AUTOSAR XML (schema 00046)
package /ComponentTypes
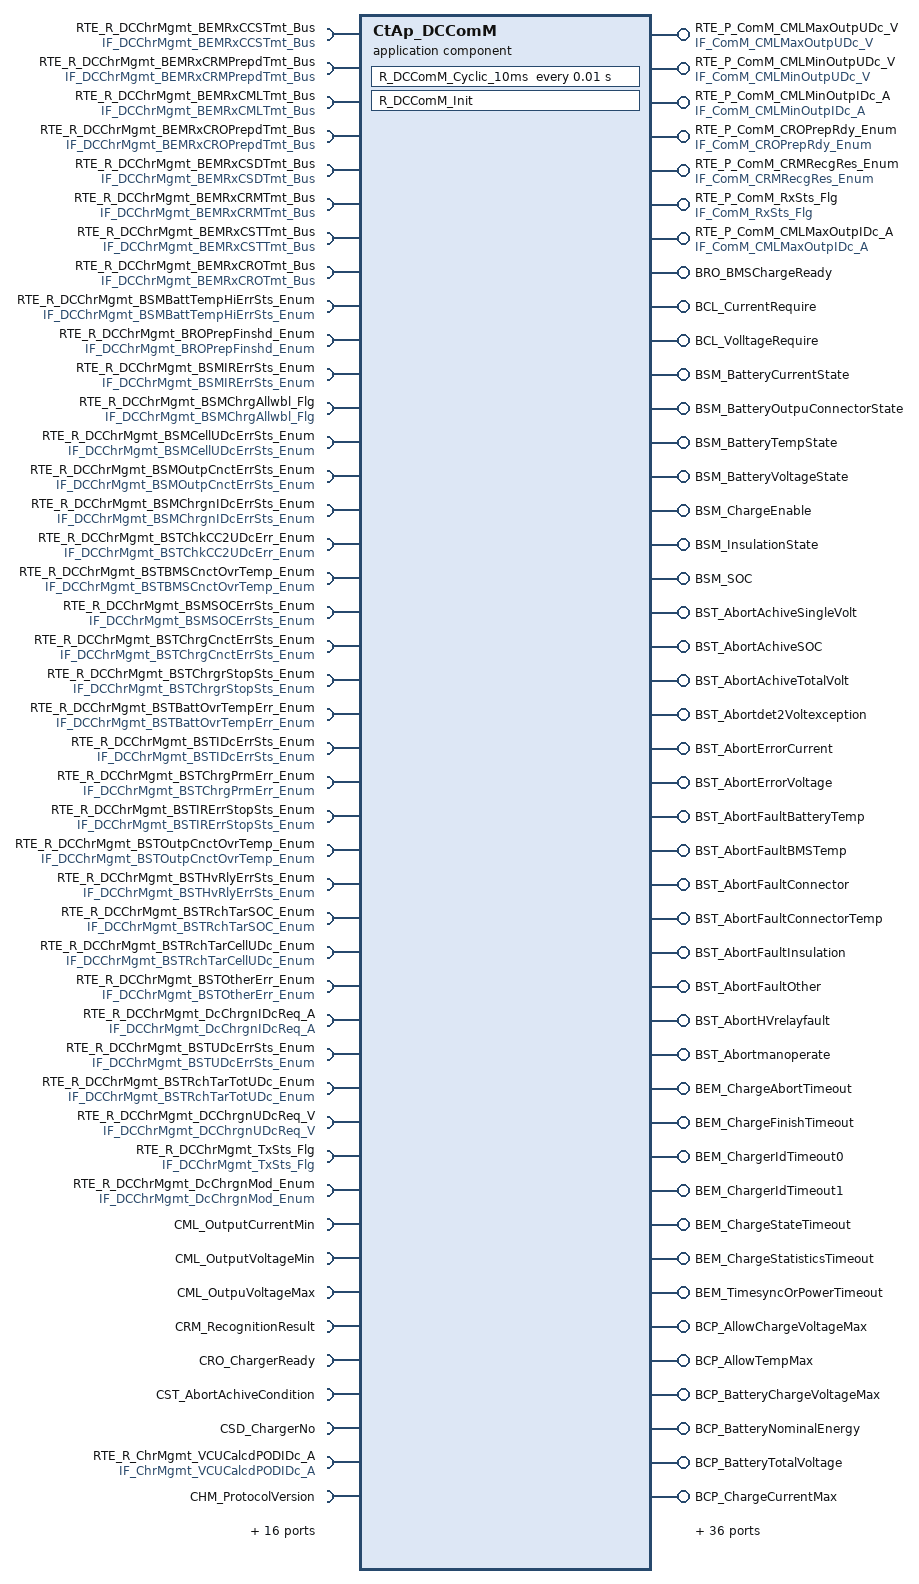
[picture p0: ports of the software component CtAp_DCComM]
  application sw component type CtAp_DCComM
    7 x provide port:
      RTE_P_ComM_CMLMaxOutpUDc_V: nonqueued-sender-com-spec{data-element=tec_ComM_CMLMaxOutpUDc_V, init-value=0}, provided-interface=IF_ComM_CMLMaxOutpUDc_V
      RTE_P_ComM_CMLMinOutpUDc_V: nonqueued-sender-com-spec{data-element=tec_ComM_CMLMinOutpUDc_V, init-value=0}, provided-interface=IF_ComM_CMLMinOutpUDc_V
      RTE_P_ComM_CMLMinOutpIDc_A: nonqueued-sender-com-spec{data-element=tec_ComM_CMLMinOutpIDc_A, init-value=0}, provided-interface=IF_ComM_CMLMinOutpIDc_A
      RTE_P_ComM_CROPrepRdy_Enum: nonqueued-sender-com-spec{data-element=tec_ComM_CROPrepRdy_Enum, init-value=0}, provided-interface=IF_ComM_CROPrepRdy_Enum
      RTE_P_ComM_CRMRecgRes_Enum: nonqueued-sender-com-spec{data-element=tec_ComM_CRMRecgRes_Enum, init-value=0}, provided-interface=IF_ComM_CRMRecgRes_Enum
      RTE_P_ComM_RxSts_Flg: provided-interface=IF_ComM_RxSts_Flg
        provided-com-specs:
          data-element=tec_ComM_RxCROSts_Flg, init-value=0
          data-element=tec_ComM_RxCEMSts_Flg, init-value=0
          data-element=tec_ComM_RxCHMSts_Flg, init-value=0
          data-element=tec_ComM_RxCSTSts_Flg, init-value=0
          data-element=tec_ComM_RxCSDSts_Flg, init-value=0
          data-element=tec_ComM_RxCCSSts_Flg, init-value=0
          data-element=tec_ComM_RxCMLSts_Flg, init-value=0
          data-element=tec_ComM_RxCRMSts_Flg, init-value=0
      RTE_P_ComM_CMLMaxOutpIDc_A: nonqueued-sender-com-spec{data-element=tec_ComM_CMLMaxOutpIDc_A, init-value=0}, provided-interface=IF_ComM_CMLMaxOutpIDc_A
    35 x require port:
      RTE_R_DCChrMgmt_BEMRxCCSTmt_Bus: nonqueued-receiver-com-spec{data-element=tec_DCChrMgmt_BEMRxCCSTmt_Bus, filter=data-filter-type=ALWAYS, init-value=fields=[DCChrMgmt_MonStatBEMRxCCSTmt:0, DCChrMgmt_MonResBEMRxCCSTmt:0, DCChrMgmt_ErrStatBEMRxCCSTmt:0, DCChrMgmt_ErrResBEMRxCCSTmt:0]}, required-interface=IF_DCChrMgmt_BEMRxCCSTmt_Bus
      RTE_R_DCChrMgmt_BEMRxCRMPrepdTmt_Bus: nonqueued-receiver-com-spec{data-element=tec_DCChrMgmt_BEMRxCRMPrepdTmt_Bus, filter=data-filter-type=ALWAYS, init-value=fields=[DCChrMgmt_MonStatBEMRxCRMPrepdTmt:0, DCChrMgmt_MonResBEMRxCRMPrepdTmt:0, DCChrMgmt_ErrStatBEMRxCRMPrepdTmt:0, DCChrMgmt_ErrResBEMRxCRMPrepdTmt:0]}, required-interface=IF_DCChrMgmt_BEMRxCRMPrepdTmt_Bus
      RTE_R_DCChrMgmt_BEMRxCMLTmt_Bus: nonqueued-receiver-com-spec{data-element=tec_DCChrMgmt_BEMRxCMLTmt_Bus, filter=data-filter-type=ALWAYS, init-value=fields=[DCChrMgmt_MonStatBEMRxCMLTmt:0, DCChrMgmt_MonResBEMRxCMLTmt:0, DCChrMgmt_ErrStatBEMRxCMLTmt:0, DCChrMgmt_ErrResBEMRxCMLTmt:0]}, required-interface=IF_DCChrMgmt_BEMRxCMLTmt_Bus
      RTE_R_DCChrMgmt_BEMRxCROPrepdTmt_Bus: nonqueued-receiver-com-spec{data-element=tec_DCChrMgmt_BEMRxCROPrepdTmt_Bus, filter=data-filter-type=ALWAYS, init-value=fields=[DCChrMgmt_MonStatBEMRxCROPrepdTmt:0, DCChrMgmt_MonResBEMRxCROPrepdTmt:0, DCChrMgmt_ErrStatBEMRxCROPrepdTmt:0, DCChrMgmt_ErrResBEMRxCROPrepdTmt:0]}, required-interface=IF_DCChrMgmt_BEMRxCROPrepdTmt_Bus
      RTE_R_DCChrMgmt_BEMRxCSDTmt_Bus: nonqueued-receiver-com-spec{data-element=tec_DCChrMgmt_BEMRxCSDTmt_Bus, filter=data-filter-type=ALWAYS, init-value=fields=[DCChrMgmt_MonStatBEMRxCSDTmt:0, DCChrMgmt_MonResBEMRxCSDTmt:0, DCChrMgmt_ErrStatBEMRxCSDTmt:0, DCChrMgmt_ErrResBEMRxCSDTmt:0]}, required-interface=IF_DCChrMgmt_BEMRxCSDTmt_Bus
      RTE_R_DCChrMgmt_BEMRxCRMTmt_Bus: nonqueued-receiver-com-spec{data-element=tec_DCChrMgmt_BEMRxCRMTmt_Bus, filter=data-filter-type=ALWAYS, init-value=fields=[DCChrMgmt_MonStatBEMRxCRMTmt:0, DCChrMgmt_MonResBEMRxCRMTmt:0, DCChrMgmt_ErrStatBEMRxCRMTmt:0, DCChrMgmt_ErrResBEMRxCRMTmt:0]}, required-interface=IF_DCChrMgmt_BEMRxCRMTmt_Bus
      RTE_R_DCChrMgmt_BEMRxCSTTmt_Bus: nonqueued-receiver-com-spec{data-element=tec_DCChrMgmt_BEMRxCSTTmt_Bus, filter=data-filter-type=ALWAYS, init-value=fields=[DCChrMgmt_MonStatBEMRxCSTTmt:0, DCChrMgmt_MonResBEMRxCSTTmt:0, DCChrMgmt_ErrStatBEMRxCSTTmt:0, DCChrMgmt_ErrResBEMRxCSTTmt:0]}, required-interface=IF_DCChrMgmt_BEMRxCSTTmt_Bus
      RTE_R_DCChrMgmt_BEMRxCROTmt_Bus: nonqueued-receiver-com-spec{data-element=tec_DCChrMgmt_BEMRxCROTmt_Bus, filter=data-filter-type=ALWAYS, init-value=fields=[DCChrMgmt_MonStatBEMRxCROTmt:0, DCChrMgmt_MonResBEMRxCROTmt:0, DCChrMgmt_ErrStatBEMRxCROTmt:0, DCChrMgmt_ErrResBEMRxCROTmt:0]}, required-interface=IF_DCChrMgmt_BEMRxCROTmt_Bus
      RTE_R_DCChrMgmt_BSMBattTempHiErrSts_Enum: nonqueued-receiver-com-spec{data-element=tec_DCChrMgmt_BSMBattTempHiErrSts_Enum, filter=data-filter-type=ALWAYS, init-value=0}, required-interface=IF_DCChrMgmt_BSMBattTempHiErrSts_Enum
      RTE_R_DCChrMgmt_BROPrepFinshd_Enum: nonqueued-receiver-com-spec{data-element=tec_DCChrMgmt_BROPrepFinshd_Enum, filter=data-filter-type=ALWAYS, init-value=0}, required-interface=IF_DCChrMgmt_BROPrepFinshd_Enum
      RTE_R_DCChrMgmt_BSMIRErrSts_Enum: nonqueued-receiver-com-spec{data-element=tec_DCChrMgmt_BSMIRErrSts_Enum, filter=data-filter-type=ALWAYS, init-value=0}, required-interface=IF_DCChrMgmt_BSMIRErrSts_Enum
      RTE_R_DCChrMgmt_BSMChrgAllwbl_Flg: nonqueued-receiver-com-spec{data-element=tec_DCChrMgmt_BSMChrgAllwbl_Flg, filter=data-filter-type=ALWAYS, init-value=0}, required-interface=IF_DCChrMgmt_BSMChrgAllwbl_Flg
      RTE_R_DCChrMgmt_BSMCellUDcErrSts_Enum: nonqueued-receiver-com-spec{data-element=tec_DCChrMgmt_BSMCellUDcErrSts_Enum, filter=data-filter-type=ALWAYS, init-value=0}, required-interface=IF_DCChrMgmt_BSMCellUDcErrSts_Enum
      RTE_R_DCChrMgmt_BSMOutpCnctErrSts_Enum: nonqueued-receiver-com-spec{data-element=tec_DCChrMgmt_BSMOutpCnctErrSts_Enum, filter=data-filter-type=ALWAYS, init-value=0}, required-interface=IF_DCChrMgmt_BSMOutpCnctErrSts_Enum
      RTE_R_DCChrMgmt_BSMChrgnIDcErrSts_Enum: nonqueued-receiver-com-spec{data-element=tec_DCChrMgmt_BSMChrgnIDcErrSts_Enum, filter=data-filter-type=ALWAYS, init-value=0}, required-interface=IF_DCChrMgmt_BSMChrgnIDcErrSts_Enum
      RTE_R_DCChrMgmt_BSTChkCC2UDcErr_Enum: nonqueued-receiver-com-spec{data-element=tec_DCChrMgmt_BSTChkCC2UDcErr_Enum, filter=data-filter-type=ALWAYS, init-value=0}, required-interface=IF_DCChrMgmt_BSTChkCC2UDcErr_Enum
      RTE_R_DCChrMgmt_BSTBMSCnctOvrTemp_Enum: nonqueued-receiver-com-spec{data-element=tec_DCChrMgmt_BSTBMSCnctOvrTemp_Enum, filter=data-filter-type=ALWAYS, init-value=0}, required-interface=IF_DCChrMgmt_BSTBMSCnctOvrTemp_Enum
      RTE_R_DCChrMgmt_BSMSOCErrSts_Enum: nonqueued-receiver-com-spec{data-element=tec_DCChrMgmt_BSMSOCErrSts_Enum, filter=data-filter-type=ALWAYS, init-value=0}, required-interface=IF_DCChrMgmt_BSMSOCErrSts_Enum
      RTE_R_DCChrMgmt_BSTChrgCnctErrSts_Enum: nonqueued-receiver-com-spec{data-element=tec_DCChrMgmt_BSTChrgCnctErrSts_Enum, filter=data-filter-type=ALWAYS, init-value=0}, required-interface=IF_DCChrMgmt_BSTChrgCnctErrSts_Enum
      RTE_R_DCChrMgmt_BSTChrgrStopSts_Enum: nonqueued-receiver-com-spec{data-element=tec_DCChrMgmt_BSTChrgrStopSts_Enum, filter=data-filter-type=ALWAYS, init-value=0}, required-interface=IF_DCChrMgmt_BSTChrgrStopSts_Enum
      RTE_R_DCChrMgmt_BSTBattOvrTempErr_Enum: nonqueued-receiver-com-spec{data-element=tec_DCChrMgmt_BSTBattOvrTempErr_Enum, filter=data-filter-type=ALWAYS, init-value=0}, required-interface=IF_DCChrMgmt_BSTBattOvrTempErr_Enum
      RTE_R_DCChrMgmt_BSTIDcErrSts_Enum: nonqueued-receiver-com-spec{data-element=tec_DCChrMgmt_BSTIDcErrSts_Enum, filter=data-filter-type=ALWAYS, init-value=0}, required-interface=IF_DCChrMgmt_BSTIDcErrSts_Enum
      RTE_R_DCChrMgmt_BSTChrgPrmErr_Enum: nonqueued-receiver-com-spec{data-element=tec_DCChrMgmt_BSTChrgPrmErr_Enum, filter=data-filter-type=ALWAYS, init-value=0}, required-interface=IF_DCChrMgmt_BSTChrgPrmErr_Enum
      RTE_R_DCChrMgmt_BSTIRErrStopSts_Enum: nonqueued-receiver-com-spec{data-element=tec_DCChrMgmt_BSTIRErrStopSts_Enum, filter=data-filter-type=ALWAYS, init-value=0}, required-interface=IF_DCChrMgmt_BSTIRErrStopSts_Enum
      RTE_R_DCChrMgmt_BSTOutpCnctOvrTemp_Enum: nonqueued-receiver-com-spec{data-element=tec_DCChrMgmt_BSTOutpCnctOvrTemp_Enum, filter=data-filter-type=ALWAYS, init-value=0}, required-interface=IF_DCChrMgmt_BSTOutpCnctOvrTemp_Enum
      RTE_R_DCChrMgmt_BSTHvRlyErrSts_Enum: nonqueued-receiver-com-spec{data-element=tec_DCChrMgmt_BSTHvRlyErrSts_Enum, filter=data-filter-type=ALWAYS, init-value=0}, required-interface=IF_DCChrMgmt_BSTHvRlyErrSts_Enum
      RTE_R_DCChrMgmt_BSTRchTarSOC_Enum: nonqueued-receiver-com-spec{data-element=tec_DCChrMgmt_BSTRchTarSOC_Enum, filter=data-filter-type=ALWAYS, init-value=0}, required-interface=IF_DCChrMgmt_BSTRchTarSOC_Enum
      RTE_R_DCChrMgmt_BSTRchTarCellUDc_Enum: nonqueued-receiver-com-spec{data-element=tec_DCChrMgmt_BSTRchTarCellUDc_Enum, filter=data-filter-type=ALWAYS, init-value=0}, required-interface=IF_DCChrMgmt_BSTRchTarCellUDc_Enum
      RTE_R_DCChrMgmt_BSTOtherErr_Enum: nonqueued-receiver-com-spec{data-element=tec_DCChrMgmt_BSTOtherErr_Enum, filter=data-filter-type=ALWAYS, init-value=0}, required-interface=IF_DCChrMgmt_BSTOtherErr_Enum
      RTE_R_DCChrMgmt_DcChrgnIDcReq_A: nonqueued-receiver-com-spec{data-element=tec_DCChrMgmt_DcChrgnIDcReq_A, filter=data-filter-type=ALWAYS, init-value=0}, required-interface=IF_DCChrMgmt_DcChrgnIDcReq_A
      RTE_R_DCChrMgmt_BSTUDcErrSts_Enum: nonqueued-receiver-com-spec{data-element=tec_DCChrMgmt_BSTUDcErrSts_Enum, filter=data-filter-type=ALWAYS, init-value=0}, required-interface=IF_DCChrMgmt_BSTUDcErrSts_Enum
      RTE_R_DCChrMgmt_BSTRchTarTotUDc_Enum: nonqueued-receiver-com-spec{data-element=tec_DCChrMgmt_BSTRchTarTotUDc_Enum, filter=data-filter-type=ALWAYS, init-value=0}, required-interface=IF_DCChrMgmt_BSTRchTarTotUDc_Enum
      RTE_R_DCChrMgmt_DCChrgnUDcReq_V: nonqueued-receiver-com-spec{data-element=tec_DCChrMgmt_DcChrgnUDcReq_V, filter=data-filter-type=ALWAYS, init-value=0}, required-interface=IF_DCChrMgmt_DCChrgnUDcReq_V
      RTE_R_DCChrMgmt_TxSts_Flg: required-interface=IF_DCChrMgmt_TxSts_Flg
        required-com-specs:
          data-element=tec_DCChrMgmt_TxBSDSts_Flg, filter=data-filter-type=ALWAYS, init-value=0
          data-element=tec_DCChrMgmt_TxBEMSts_Flg, filter=data-filter-type=ALWAYS, init-value=0
          data-element=tec_DCChrMgmt_TxBSMSts_Flg, filter=data-filter-type=ALWAYS, init-value=0
          data-element=tec_DCChrMgmt_TxBCSSts_Flg, filter=data-filter-type=ALWAYS, init-value=0
          data-element=tec_DCChrMgmt_TxBSTSts_Flg, filter=data-filter-type=ALWAYS, init-value=0
          data-element=tec_DCChrMgmt_TxBCLSts_Flg, filter=data-filter-type=ALWAYS, init-value=0
          data-element=tec_DCChrMgmt_TxBROSts_Flg, filter=data-filter-type=ALWAYS, init-value=0
          data-element=tec_DCChrMgmt_TxBCPSts_Flg, filter=data-filter-type=ALWAYS, init-value=0
          data-element=tec_DCChrMgmt_TxBRMSts_Flg, filter=data-filter-type=ALWAYS, init-value=0
          data-element=tec_DCChrMgmt_TxBHMSts_Flg, filter=data-filter-type=ALWAYS, init-value=0
      RTE_R_DCChrMgmt_DcChrgnMod_Enum: nonqueued-receiver-com-spec{data-element=tec_DCChrMgmt_DcChrgnMod_Enum, filter=data-filter-type=ALWAYS, init-value=0}, required-interface=IF_DCChrMgmt_DcChrgnMod_Enum
    31 x provide port:
      BRO_BMSChargeReady: nonqueued-sender-com-spec{data-element=BRO_BMSChargeReady, init-value=0}, provided-interface=BRO_BMSChargeReady
      BCL_CurrentRequire: nonqueued-sender-com-spec{data-element=BCL_CurrentRequire, init-value=-400}, provided-interface=BCL_CurrentRequire
      BCL_VolltageRequire: nonqueued-sender-com-spec{data-element=BCL_VolltageRequire, init-value=0}, provided-interface=BCL_VolltageRequire
      BSM_BatteryCurrentState: nonqueued-sender-com-spec{data-element=BSM_BatteryCurrentState, init-value=0}, provided-interface=BSM_BatteryCurrentState
      BSM_BatteryOutpuConnectorState: nonqueued-sender-com-spec{data-element=BSM_BatteryOutpuConnectorState, init-value=0}, provided-interface=BSM_BatteryOutpuConnectorState
      BSM_BatteryTempState: nonqueued-sender-com-spec{data-element=BSM_BatteryTempState, init-value=0}, provided-interface=BSM_BatteryTempState
      BSM_BatteryVoltageState: nonqueued-sender-com-spec{data-element=BSM_BatteryVoltageState, init-value=0}, provided-interface=BSM_BatteryVoltageState
      BSM_ChargeEnable: nonqueued-sender-com-spec{data-element=BSM_ChargeEnable, init-value=0}, provided-interface=BSM_ChargeEnable
      BSM_InsulationState: nonqueued-sender-com-spec{data-element=BSM_InsulationState, init-value=0}, provided-interface=BSM_InsulationState
      BSM_SOC: nonqueued-sender-com-spec{data-element=BSM_SOC, init-value=0}, provided-interface=BSM_SOC
      BST_AbortAchiveSingleVolt: nonqueued-sender-com-spec{data-element=BST_AbortAchiveSingleVolt, init-value=0}, provided-interface=BST_AbortAchiveSingleVolt
      BST_AbortAchiveSOC: nonqueued-sender-com-spec{data-element=BST_AbortAchiveSOC, init-value=0}, provided-interface=BST_AbortAchiveSOC
      BST_AbortAchiveTotalVolt: nonqueued-sender-com-spec{data-element=BST_AbortAchiveTotalVolt, init-value=0}, provided-interface=BST_AbortAchiveTotalVolt
      BST_Abortdet2Voltexception: nonqueued-sender-com-spec{data-element=BST_Abortdet2Voltexception, init-value=0}, provided-interface=BST_Abortdet2Voltexception
      BST_AbortErrorCurrent: nonqueued-sender-com-spec{data-element=BST_AbortErrorCurrent, init-value=0}, provided-interface=BST_AbortErrorCurrent
      BST_AbortErrorVoltage: nonqueued-sender-com-spec{data-element=BST_AbortErrorVoltage, init-value=0}, provided-interface=BST_AbortErrorVoltage
      BST_AbortFaultBatteryTemp: nonqueued-sender-com-spec{data-element=BST_AbortFaultBatteryTemp, init-value=0}, provided-interface=BST_AbortFaultBatteryTemp
      BST_AbortFaultBMSTemp: nonqueued-sender-com-spec{data-element=BST_AbortFaultBMSTemp, init-value=0}, provided-interface=BST_AbortFaultBMSTemp
      BST_AbortFaultConnector: nonqueued-sender-com-spec{data-element=BST_AbortFaultConnector, init-value=0}, provided-interface=BST_AbortFaultConnector
      BST_AbortFaultConnectorTemp: nonqueued-sender-com-spec{data-element=BST_AbortFaultConnectorTemp, init-value=0}, provided-interface=BST_AbortFaultConnectorTemp
      BST_AbortFaultInsulation: nonqueued-sender-com-spec{data-element=BST_AbortFaultInsulation, init-value=0}, provided-interface=BST_AbortFaultInsulation
      BST_AbortFaultOther: nonqueued-sender-com-spec{data-element=BST_AbortFaultOther, init-value=0}, provided-interface=BST_AbortFaultOther
      BST_AbortHVrelayfault: nonqueued-sender-com-spec{data-element=BST_AbortHVrelayfault, init-value=0}, provided-interface=BST_AbortHVrelayfault
      BST_Abortmanoperate: nonqueued-sender-com-spec{data-element=BST_Abortmanoperate, init-value=0}, provided-interface=BST_Abortmanoperate
      BEM_ChargeAbortTimeout: nonqueued-sender-com-spec{data-element=BEM_ChargeAbortTimeout, init-value=0}, provided-interface=BEM_ChargeAbortTimeout
      BEM_ChargeFinishTimeout: nonqueued-sender-com-spec{data-element=BEM_ChargeFinishTimeout, init-value=0}, provided-interface=BEM_ChargeFinishTimeout
      BEM_ChargerIdTimeout0: nonqueued-sender-com-spec{data-element=BEM_ChargerIdTimeout0, init-value=0}, provided-interface=BEM_ChargerIdTimeout0
      BEM_ChargerIdTimeout1: nonqueued-sender-com-spec{data-element=BEM_ChargerIdTimeout1, init-value=0}, provided-interface=BEM_ChargerIdTimeout1
      BEM_ChargeStateTimeout: nonqueued-sender-com-spec{data-element=BEM_ChargeStateTimeout, init-value=0}, provided-interface=BEM_ChargeStateTimeout
      BEM_ChargeStatisticsTimeout: nonqueued-sender-com-spec{data-element=BEM_ChargeStatisticsTimeout, init-value=0}, provided-interface=BEM_ChargeStatisticsTimeout
      BEM_TimesyncOrPowerTimeout: nonqueued-sender-com-spec{data-element=BEM_TimesyncOrPowerTimeout, init-value=0}, provided-interface=BEM_TimesyncOrPowerTimeout
    8 x require port:
      CML_OutputCurrentMin: nonqueued-receiver-com-spec{data-element=CML_OutputCurrentMin, init-value=0}, required-interface=CML_OutputCurrentMin
      CML_OutputVoltageMin: nonqueued-receiver-com-spec{data-element=CML_OutputVoltageMin, init-value=0}, required-interface=CML_OutputVoltageMin
      CML_OutpuVoltageMax: nonqueued-receiver-com-spec{data-element=CML_OutpuVoltageMax, enable-update=true, init-value=0}, required-interface=CML_OutpuVoltageMax
      CRM_RecognitionResult: nonqueued-receiver-com-spec{data-element=CRM_RecognitionResult, enable-update=true, init-value=1}, required-interface=CRM_RecognitionResult
      CRO_ChargerReady: nonqueued-receiver-com-spec{data-element=CRO_ChargerReady, enable-update=true, init-value=0}, required-interface=CRO_ChargerReady
      CST_AbortAchiveCondition: nonqueued-receiver-com-spec{data-element=CST_AbortAchiveCondition, enable-update=true, init-value=0}, required-interface=CST_AbortAchiveCondition
      CSD_ChargerNo: nonqueued-receiver-com-spec{data-element=CSD_ChargerNo, enable-update=true, init-value=1}, required-interface=CSD_ChargerNo
      RTE_R_ChrMgmt_VCUCalcdPODIDc_A: nonqueued-receiver-com-spec{data-element=tec_ChrMgmt_VCUCalcdPODIDc_A, filter=data-filter-type=ALWAYS, init-value=0}, required-interface=IF_ChrMgmt_VCUCalcdPODIDc_A
    38 x provide port:
      BCP_AllowChargeVoltageMax: queued-sender-com-spec=BCP_AllowChargeVoltageMax, provided-interface=BCP_AllowChargeVoltageMax
      BCP_AllowTempMax: queued-sender-com-spec=BCP_AllowTempMax, provided-interface=BCP_AllowTempMax
      BCP_BatteryChargeVoltageMax: queued-sender-com-spec=BCP_BatteryChargeVoltageMax, provided-interface=BCP_BatteryChargeVoltageMax
      BCP_BatteryNominalEnergy: queued-sender-com-spec=BCP_BatteryNominalEnergy, provided-interface=BCP_BatteryNominalEnergy
      BCP_BatteryTotalVoltage: queued-sender-com-spec=BCP_BatteryTotalVoltage, provided-interface=BCP_BatteryTotalVoltage
      BCP_ChargeCurrentMax: queued-sender-com-spec=BCP_ChargeCurrentMax, provided-interface=BCP_ChargeCurrentMax
      BCP_SOC: queued-sender-com-spec=BCP_SOC, provided-interface=BCP_SOC
      BCS_BatteryVoltMax: queued-sender-com-spec=BCS_BatteryVoltMax, provided-interface=BCS_BatteryVoltMax
      BCS_BatteryVoltMaxGroup: queued-sender-com-spec=BCS_BatteryVoltMaxGroup, provided-interface=BCS_BatteryVoltMaxGroup
      BCS_ChargeCurrentMeasure: queued-sender-com-spec=BCS_ChargeCurrentMeasure, provided-interface=BCS_ChargeCurrentMeasure
      BCS_ChargeVoltageMeasure: queued-sender-com-spec=BCS_ChargeVoltageMeasure, provided-interface=BCS_ChargeVoltageMeasure
      BCS_EstimatedTimeRemaining: queued-sender-com-spec=BCS_EstimatedTimeRemaining, provided-interface=BCS_EstimatedTimeRemaining
      BCS_SOC: queued-sender-com-spec=BCS_SOC, provided-interface=BCS_SOC
      BRM_BatteryChargeTimes: queued-sender-com-spec=BRM_BatteryChargeTimes, provided-interface=BRM_BatteryChargeTimes
      BRM_BatteryProductDay: queued-sender-com-spec=BRM_BatteryProductDay, provided-interface=BRM_BatteryProductDay
      BRM_BatteryProductMonth: queued-sender-com-spec=BRM_BatteryProductMonth, provided-interface=BRM_BatteryProductMonth
      BRM_BatteryProductYear: queued-sender-com-spec=BRM_BatteryProductYear, provided-interface=BRM_BatteryProductYear
      BRM_BatteryProperty: queued-sender-com-spec=BRM_BatteryProperty, provided-interface=BRM_BatteryProperty
      BRM_BatterySN: queued-sender-com-spec=BRM_BatterySN, provided-interface=BRM_BatterySN
      BRM_BatterySystemRatedCapacity: queued-sender-com-spec=BRM_BatterySystemRatedCapacity, provided-interface=BRM_BatterySystemRatedCapacity
      BRM_BatterySystemRatedVoltage: queued-sender-com-spec=BRM_BatterySystemRatedVoltage, provided-interface=BRM_BatterySystemRatedVoltage
      BRM_BatteryType: queued-sender-com-spec=BRM_BatteryType, provided-interface=BRM_BatteryType
      BRM_Manufacturer: queued-sender-com-spec=BRM_Manufacturer, provided-interface=BRM_Manufacturer
      BRM_ProtocolVersion: queued-sender-com-spec=BRM_ProtocolVersion, provided-interface=BRM_ProtocolVersion
      BRM_VehicleIdByte1_8: queued-sender-com-spec=BRM_VehicleIdByte1_8, provided-interface=BRM_VehicleIdByte1_8
      BRM_VehicleIdByte17: queued-sender-com-spec=BRM_VehicleIdByte17, provided-interface=BRM_VehicleIdByte17
      BRM_VehicleIdByte9_16: queued-sender-com-spec=BRM_VehicleIdByte9_16, provided-interface=BRM_VehicleIdByte9_16
      BSD_AbortSOC: nonqueued-sender-com-spec{data-element=BSD_AbortSOC, init-value=0}, provided-interface=BSD_AbortSOC
      BSD_BatteryTempMax: nonqueued-sender-com-spec{data-element=BSD_BatteryTempMax, init-value=0}, provided-interface=BSD_BatteryTempMax
      BSD_BatteryTempMin: nonqueued-sender-com-spec{data-element=BSD_BatteryTempMin, init-value=0}, provided-interface=BSD_BatteryTempMin
      BSD_BatteryVoltageMax: nonqueued-sender-com-spec{data-element=BSD_BatteryVoltageMax, init-value=0}, provided-interface=BSD_BatteryVoltageMax
      BSD_BatteryVoltageMin: nonqueued-sender-com-spec{data-element=BSD_BatteryVoltageMin, init-value=0}, provided-interface=BSD_BatteryVoltageMin
      BSM_BatteryTempMax: nonqueued-sender-com-spec{data-element=BSM_BatteryTempMax, init-value=0}, provided-interface=BSM_BatteryTempMax
      BSM_BatteryTempMaxNo: nonqueued-sender-com-spec{data-element=BSM_BatteryTempMaxNo, init-value=0}, provided-interface=BSM_BatteryTempMaxNo
      BSM_BatteryTempMin: nonqueued-sender-com-spec{data-element=BSM_BatteryTempMin, init-value=0}, provided-interface=BSM_BatteryTempMin
      BSM_BatteryTempMinNo: nonqueued-sender-com-spec{data-element=BSM_BatteryTempMinNo, init-value=0}, provided-interface=BSM_BatteryTempMinNo
      BSM_BatteryVoltageMaxNo: nonqueued-sender-com-spec{data-element=BSM_BatteryVoltageMaxNo, init-value=0}, provided-interface=BSM_BatteryVoltageMaxNo
      BHM_AllowChargeVoltageMax: nonqueued-sender-com-spec{data-element=BHM_AllowChargeVoltageMax, init-value=0}, provided-interface=BHM_AllowChargeVoltageMax
    5 x require port:
      CHM_ProtocolVersion: nonqueued-receiver-com-spec{data-element=CHM_ProtocolVersion, enable-update=true, filter=data-filter-type=ALWAYS, init-value=0}, required-interface=CHM_ProtocolVersion
      CTS_Year: nonqueued-receiver-com-spec{data-element=CTS_Year, enable-update=true, init-value=0}, required-interface=CTS_Year
      CCS_OutputVoltage: nonqueued-receiver-com-spec{data-element=CCS_OutputVoltage, enable-update=true, filter=data-filter-type=ALWAYS, init-value=0}, required-interface=CCS_OutputVoltage
      CEM_BatteryChargeRequireTimeout: nonqueued-receiver-com-spec{data-element=CEM_BatteryChargeRequireTimeout, enable-update=true, filter=data-filter-type=ALWAYS, init-value=0}, required-interface=CEM_BatteryChargeRequireTimeout
      CML_OutputCurrentMax: nonqueued-receiver-com-spec{data-element=CML_OutputCurrentMax, filter=data-filter-type=ALWAYS, init-value=0}, required-interface=CML_OutputCurrentMax
    provide port BCL_ChargeMode: nonqueued-sender-com-spec{data-element=BCL_ChargeMode, init-value=0}, provided-interface=BCL_ChargeMode
    require port CCS_OutputCurrent: nonqueued-receiver-com-spec{data-element=CCS_OutputCurrent, filter=data-filter-type=ALWAYS, init-value=0}, required-interface=CCS_OutputCurrent
    provide port RTE_P_ComM_CCSOutpIDc_A: nonqueued-sender-com-spec{data-element=tec_ComM_CCSOutpIDc_A, init-value=0}, provided-interface=IF_ComM_CCSOutpIDc_A
    provide port RTE_P_ComM_CCSOutpUDc_V: nonqueued-sender-com-spec{data-element=tec_ComM_CCSOutpUDc_V, init-value=0}, provided-interface=IF_ComM_CCSOutpUDc_V
    11 x require port:
      SG_BMS_BatInfor_01_SigGroup: nonqueued-receiver-com-spec{data-element=SG_BMS_BatInfor_01_SigGroup, filter=data-filter-type=ALWAYS, init-value=fields=[BMS_BatType:0, BMS_CellNumbers:0, BMS_RatBatVoltage:0, BMS_RatCapacity:0, BMS_RatEnergy:0]}, required-interface=SG_BMS_BatInfor_01_SigGroup
      SG_BMS_BatInfor_02_SigGroup: nonqueued-receiver-com-spec{data-element=SG_BMS_BatInfor_02_SigGroup, filter=data-filter-type=ALWAYS, init-value=fields=BMS_BatSupName:0}, required-interface=SG_BMS_BatInfor_02_SigGroup
      SG_BMS_CellTemp_SigGroup: nonqueued-receiver-com-spec{data-element=SG_BMS_CellTemp_SigGroup, enable-update=true, filter=data-filter-type=ALWAYS, init-value=fields=[BMS_AverageCellTemp:215, BMS_MaxCellTemp:215, BMS_MaxCellTempNO:0, BMS_MinCellTemp:215, BMS_MinCellTempNO:0, BMS_MinCellTempModuleNO:0]}, required-interface=SG_BMS_CellTemp_SigGroup_1
      SG_BMS_CellVoltage_SigGroup: nonqueued-receiver-com-spec{data-element=SG_BMS_CellVoltage_SigGroup, enable-update=true, filter=data-filter-type=ALWAYS, init-value=fields=[BMS_MaxCellVoltage:0, BMS_MaxCellVoltageModuleNO:0, BMS_MaxCellVoltageNO:0, BMS_MinCellVoltage:0]}, required-interface=SG_BMS_CellVoltage_SigGroup_1
      SG_BMS_Charge_03_SigGroup: nonqueued-receiver-com-spec{data-element=SG_BMS_Charge_03_SigGroup, filter=data-filter-type=ALWAYS, init-value=fields=[BMS_BatChagSum:0, BMS_SingChgkwh:0, BMS_SumChgkwh:0]}, required-interface=SG_BMS_Charge_03_SigGroup
      SG_BMS_PRO_SigGroup: nonqueued-receiver-com-spec{data-element=SG_BMS_PRO_SigGroup, filter=data-filter-type=ALWAYS, init-value=fields=[BMS_BatProDatDay:0, BMS_BatProDatMonth:0, BMS_BatProDatYear:0]}, required-interface=SG_BMS_PRO_SigGroup
      SG_BMS_status_03_SigGroup: nonqueued-receiver-com-spec{data-element=SG_BMS_status_03_SigGroup, filter=data-filter-type=ALWAYS, init-value=fields=[BMS_DisplaySOC:0, BMS_LinkVoltage:0, BMS_PackVoltage:0]}, required-interface=SG_BMS_status_03_SigGroup
      SG_BMS_TCU_SigGroup: nonqueued-receiver-com-spec{data-element=SG_BMS_TCU_SigGroup, filter=data-filter-type=ALWAYS, init-value=fields=[BMS_AllowCellTemperature:255, BMS_KeepWarmRequest:0, BMS_KeepWarmStatus:0, BMS_RTC_Request:0]}, required-interface=SG_BMS_TCU_SigGroup
      SG_BMS_VersionInfor_SigGroup: nonqueued-receiver-com-spec{data-element=SG_BMS_VersionInfor_SigGroup, filter=data-filter-type=ALWAYS, init-value=fields=[BMS_BatProRights:0, BMS_ComVersion:0]}, required-interface=SG_BMS_VersionInfor_SigGroup
      SG_POD_Status_01_SigGroup: nonqueued-receiver-com-spec{data-element=SG_POD_Status_01_SigGroup, filter=data-filter-type=ALWAYS, init-value=fields=[POD_DCFCVoltage:0, POD_DCInletTempA:0, POD_DCInletTempB:0]}, required-interface=SG_POD_Status_01_SigGroup
      SG_BMS_Charge_01_SigGroup: nonqueued-receiver-com-spec{data-element=SG_BMS_Charge_01_SigGroup, filter=data-filter-type=ALWAYS, init-value=fields=[BMS_AllowChagCurrent:0, BMS_MaxChagVoltage:0, BMS_RemChagTime:0]}, required-interface=SG_BMS_Charge_01_SigGroup
    provide port BST_AbortChargparameter: nonqueued-sender-com-spec{data-element=BST_AbortChargparameter, init-value=0}, provided-interface=BST_AbortChargparameter
    behavior CtAp_DCComM_InternalBehavior
      timing event TMT_R_DCComM_Cyclic_10ms: start-on-event=R_DCComM_Cyclic_10ms, period=0.01
      init event CtAp_DCComM_InitEvent: start-on-event=R_DCComM_Init
      runnable R_DCComM_Cyclic_10ms
        data-receive-point-by-arguments:
          69 x access:
            REC_CCS_OutputVoltage_CCS_OutputVoltage: accessed-variable=CCS_OutputVoltage.CCS_OutputVoltage
            REC_CEM_BatteryChargeRequireTimeout_CEM_BatteryChargeRequireTimeout: accessed-variable=CEM_BatteryChargeRequireTimeout.CEM_BatteryChargeRequireTimeout
            REC_CHM_ProtocolVersion_CHM_ProtocolVersion: accessed-variable=CHM_ProtocolVersion.CHM_ProtocolVersion
            REC_CML_OutpuVoltageMax_CML_OutpuVoltageMax: accessed-variable=CML_OutpuVoltageMax.CML_OutpuVoltageMax
            REC_CML_OutputCurrentMin_CML_OutputCurrentMin: accessed-variable=CML_OutputCurrentMin.CML_OutputCurrentMin
            REC_CML_OutputVoltageMin_CML_OutputVoltageMin: accessed-variable=CML_OutputVoltageMin.CML_OutputVoltageMin
            REC_CRM_RecognitionResult_CRM_RecognitionResult: accessed-variable=CRM_RecognitionResult.CRM_RecognitionResult
            REC_CRO_ChargerReady_CRO_ChargerReady: accessed-variable=CRO_ChargerReady.CRO_ChargerReady
            REC_CSD_ChargerNo_CSD_ChargerNo: accessed-variable=CSD_ChargerNo.CSD_ChargerNo
            REC_CST_AbortAchiveCondition_CST_AbortAchiveCondition: accessed-variable=CST_AbortAchiveCondition.CST_AbortAchiveCondition
            REC_CTS_Year_CTS_Year: accessed-variable=CTS_Year.CTS_Year
            REC_RTE_R_ChrMgmt_VCUCalcdPODIDc_A_tec_ChrMgmt_VCUCalcdPODIDc_A: accessed-variable=RTE_R_ChrMgmt_VCUCalcdPODIDc_A.tec_ChrMgmt_VCUCalcdPODIDc_A
            REC_RTE_R_DCChrMgmt_BEMRxCCSTmt_Bus_tec_DCChrMgmt_BEMRxCCSTmt_Bus: accessed-variable=RTE_R_DCChrMgmt_BEMRxCCSTmt_Bus.tec_DCChrMgmt_BEMRxCCSTmt_Bus
            REC_RTE_R_DCChrMgmt_BEMRxCMLTmt_Bus_tec_DCChrMgmt_BEMRxCMLTmt_Bus: accessed-variable=RTE_R_DCChrMgmt_BEMRxCMLTmt_Bus.tec_DCChrMgmt_BEMRxCMLTmt_Bus
            REC_RTE_R_DCChrMgmt_BEMRxCRMPrepdTmt_Bus_tec_DCChrMgmt_BEMRxCRMPrepdTmt_Bus: accessed-variable=RTE_R_DCChrMgmt_BEMRxCRMPrepdTmt_Bus.tec_DCChrMgmt_BEMRxCRMPrepdTmt_Bus
            REC_RTE_R_DCChrMgmt_BEMRxCRMTmt_Bus_tec_DCChrMgmt_BEMRxCRMTmt_Bus: accessed-variable=RTE_R_DCChrMgmt_BEMRxCRMTmt_Bus.tec_DCChrMgmt_BEMRxCRMTmt_Bus
            REC_RTE_R_DCChrMgmt_BEMRxCROPrepdTmt_Bus_tec_DCChrMgmt_BEMRxCROPrepdTmt_Bus: accessed-variable=RTE_R_DCChrMgmt_BEMRxCROPrepdTmt_Bus.tec_DCChrMgmt_BEMRxCROPrepdTmt_Bus
            REC_RTE_R_DCChrMgmt_BEMRxCROTmt_Bus_tec_DCChrMgmt_BEMRxCROTmt_Bus: accessed-variable=RTE_R_DCChrMgmt_BEMRxCROTmt_Bus.tec_DCChrMgmt_BEMRxCROTmt_Bus
            REC_RTE_R_DCChrMgmt_BEMRxCSDTmt_Bus_tec_DCChrMgmt_BEMRxCSDTmt_Bus: accessed-variable=RTE_R_DCChrMgmt_BEMRxCSDTmt_Bus.tec_DCChrMgmt_BEMRxCSDTmt_Bus
            REC_RTE_R_DCChrMgmt_BEMRxCSTTmt_Bus_tec_DCChrMgmt_BEMRxCSTTmt_Bus: accessed-variable=RTE_R_DCChrMgmt_BEMRxCSTTmt_Bus.tec_DCChrMgmt_BEMRxCSTTmt_Bus
            REC_RTE_R_DCChrMgmt_BROPrepFinshd_Enum_tec_DCChrMgmt_BROPrepFinshd_Enum: accessed-variable=RTE_R_DCChrMgmt_BROPrepFinshd_Enum.tec_DCChrMgmt_BROPrepFinshd_Enum
            REC_RTE_R_DCChrMgmt_BSMBattTempHiErrSts_Enum_tec_DCChrMgmt_BSMBattTempHiErrSts_Enum: accessed-variable=RTE_R_DCChrMgmt_BSMBattTempHiErrSts_Enum.tec_DCChrMgmt_BSMBattTempHiErrSts_Enum
            REC_RTE_R_DCChrMgmt_BSMCellUDcErrSts_Enum_tec_DCChrMgmt_BSMCellUDcErrSts_Enum: accessed-variable=RTE_R_DCChrMgmt_BSMCellUDcErrSts_Enum.tec_DCChrMgmt_BSMCellUDcErrSts_Enum
            REC_RTE_R_DCChrMgmt_BSMChrgAllwbl_Flg_tec_DCChrMgmt_BSMChrgAllwbl_Flg: accessed-variable=RTE_R_DCChrMgmt_BSMChrgAllwbl_Flg.tec_DCChrMgmt_BSMChrgAllwbl_Flg
            REC_RTE_R_DCChrMgmt_BSMChrgnIDcErrSts_Enum_tec_DCChrMgmt_BSMChrgnIDcErrSts_Enum: accessed-variable=RTE_R_DCChrMgmt_BSMChrgnIDcErrSts_Enum.tec_DCChrMgmt_BSMChrgnIDcErrSts_Enum
            REC_RTE_R_DCChrMgmt_BSMIRErrSts_Enum_tec_DCChrMgmt_BSMIRErrSts_Enum: accessed-variable=RTE_R_DCChrMgmt_BSMIRErrSts_Enum.tec_DCChrMgmt_BSMIRErrSts_Enum
            REC_RTE_R_DCChrMgmt_BSMOutpCnctErrSts_Enum_tec_DCChrMgmt_BSMOutpCnctErrSts_Enum: accessed-variable=RTE_R_DCChrMgmt_BSMOutpCnctErrSts_Enum.tec_DCChrMgmt_BSMOutpCnctErrSts_Enum
            REC_RTE_R_DCChrMgmt_BSMSOCErrSts_Enum_tec_DCChrMgmt_BSMSOCErrSts_Enum: accessed-variable=RTE_R_DCChrMgmt_BSMSOCErrSts_Enum.tec_DCChrMgmt_BSMSOCErrSts_Enum
            REC_RTE_R_DCChrMgmt_BSTBMSCnctOvrTemp_Enum_tec_DCChrMgmt_BSTBMSCnctOvrTemp_Enum: accessed-variable=RTE_R_DCChrMgmt_BSTBMSCnctOvrTemp_Enum.tec_DCChrMgmt_BSTBMSCnctOvrTemp_Enum
            REC_RTE_R_DCChrMgmt_BSTBattOvrTempErr_Enum_tec_DCChrMgmt_BSTBattOvrTempErr_Enum: accessed-variable=RTE_R_DCChrMgmt_BSTBattOvrTempErr_Enum.tec_DCChrMgmt_BSTBattOvrTempErr_Enum
            REC_RTE_R_DCChrMgmt_BSTChkCC2UDcErr_Enum_tec_DCChrMgmt_BSTChkCC2UDcErr_Enum: accessed-variable=RTE_R_DCChrMgmt_BSTChkCC2UDcErr_Enum.tec_DCChrMgmt_BSTChkCC2UDcErr_Enum
            REC_RTE_R_DCChrMgmt_BSTChrgCnctErrSts_Enum_tec_DCChrMgmt_BSTChrgCnctErrSts_Enum: accessed-variable=RTE_R_DCChrMgmt_BSTChrgCnctErrSts_Enum.tec_DCChrMgmt_BSTChrgCnctErrSts_Enum
            REC_RTE_R_DCChrMgmt_BSTChrgPrmErr_Enum_tec_DCChrMgmt_BSTChrgPrmErr_Enum: accessed-variable=RTE_R_DCChrMgmt_BSTChrgPrmErr_Enum.tec_DCChrMgmt_BSTChrgPrmErr_Enum
            REC_RTE_R_DCChrMgmt_BSTChrgrStopSts_Enum_tec_DCChrMgmt_BSTChrgrStopSts_Enum: accessed-variable=RTE_R_DCChrMgmt_BSTChrgrStopSts_Enum.tec_DCChrMgmt_BSTChrgrStopSts_Enum
            REC_RTE_R_DCChrMgmt_BSTHvRlyErrSts_Enum_tec_DCChrMgmt_BSTHvRlyErrSts_Enum: accessed-variable=RTE_R_DCChrMgmt_BSTHvRlyErrSts_Enum.tec_DCChrMgmt_BSTHvRlyErrSts_Enum
            REC_RTE_R_DCChrMgmt_BSTIDcErrSts_Enum_tec_DCChrMgmt_BSTIDcErrSts_Enum: accessed-variable=RTE_R_DCChrMgmt_BSTIDcErrSts_Enum.tec_DCChrMgmt_BSTIDcErrSts_Enum
            REC_RTE_R_DCChrMgmt_BSTIRErrStopSts_Enum_tec_DCChrMgmt_BSTIRErrStopSts_Enum: accessed-variable=RTE_R_DCChrMgmt_BSTIRErrStopSts_Enum.tec_DCChrMgmt_BSTIRErrStopSts_Enum
            REC_RTE_R_DCChrMgmt_BSTOtherErr_Enum_tec_DCChrMgmt_BSTOtherErr_Enum: accessed-variable=RTE_R_DCChrMgmt_BSTOtherErr_Enum.tec_DCChrMgmt_BSTOtherErr_Enum
            REC_RTE_R_DCChrMgmt_BSTOutpCnctOvrTemp_Enum_tec_DCChrMgmt_BSTOutpCnctOvrTemp_Enum: accessed-variable=RTE_R_DCChrMgmt_BSTOutpCnctOvrTemp_Enum.tec_DCChrMgmt_BSTOutpCnctOvrTemp_Enum
            REC_RTE_R_DCChrMgmt_BSTRchTarCellUDc_Enum_tec_DCChrMgmt_BSTRchTarCellUDc_Enum: accessed-variable=RTE_R_DCChrMgmt_BSTRchTarCellUDc_Enum.tec_DCChrMgmt_BSTRchTarCellUDc_Enum
            REC_RTE_R_DCChrMgmt_BSTRchTarSOC_Enum_tec_DCChrMgmt_BSTRchTarSOC_Enum: accessed-variable=RTE_R_DCChrMgmt_BSTRchTarSOC_Enum.tec_DCChrMgmt_BSTRchTarSOC_Enum
            REC_RTE_R_DCChrMgmt_BSTRchTarTotUDc_Enum_tec_DCChrMgmt_BSTRchTarTotUDc_Enum: accessed-variable=RTE_R_DCChrMgmt_BSTRchTarTotUDc_Enum.tec_DCChrMgmt_BSTRchTarTotUDc_Enum
            REC_RTE_R_DCChrMgmt_BSTUDcErrSts_Enum_tec_DCChrMgmt_BSTUDcErrSts_Enum: accessed-variable=RTE_R_DCChrMgmt_BSTUDcErrSts_Enum.tec_DCChrMgmt_BSTUDcErrSts_Enum
            REC_RTE_R_DCChrMgmt_DCChrgnUDcReq_V_tec_DCChrMgmt_DcChrgnUDcReq_V: accessed-variable=RTE_R_DCChrMgmt_DCChrgnUDcReq_V.tec_DCChrMgmt_DcChrgnUDcReq_V
            REC_RTE_R_DCChrMgmt_DcChrgnIDcReq_A_tec_DCChrMgmt_DcChrgnIDcReq_A: accessed-variable=RTE_R_DCChrMgmt_DcChrgnIDcReq_A.tec_DCChrMgmt_DcChrgnIDcReq_A
            REC_RTE_R_DCChrMgmt_DcChrgnMod_Enum_tec_DCChrMgmt_DcChrgnMod_Enum: accessed-variable=RTE_R_DCChrMgmt_DcChrgnMod_Enum.tec_DCChrMgmt_DcChrgnMod_Enum
            REC_RTE_R_DCChrMgmt_TxSts_Flg_tec_DCChrMgmt_TxBCLSts_Flg: accessed-variable=RTE_R_DCChrMgmt_TxSts_Flg.tec_DCChrMgmt_TxBCLSts_Flg
            REC_RTE_R_DCChrMgmt_TxSts_Flg_tec_DCChrMgmt_TxBCPSts_Flg: accessed-variable=RTE_R_DCChrMgmt_TxSts_Flg.tec_DCChrMgmt_TxBCPSts_Flg
            REC_RTE_R_DCChrMgmt_TxSts_Flg_tec_DCChrMgmt_TxBCSSts_Flg: accessed-variable=RTE_R_DCChrMgmt_TxSts_Flg.tec_DCChrMgmt_TxBCSSts_Flg
            REC_RTE_R_DCChrMgmt_TxSts_Flg_tec_DCChrMgmt_TxBEMSts_Flg: accessed-variable=RTE_R_DCChrMgmt_TxSts_Flg.tec_DCChrMgmt_TxBEMSts_Flg
            REC_RTE_R_DCChrMgmt_TxSts_Flg_tec_DCChrMgmt_TxBHMSts_Flg: accessed-variable=RTE_R_DCChrMgmt_TxSts_Flg.tec_DCChrMgmt_TxBHMSts_Flg
            REC_RTE_R_DCChrMgmt_TxSts_Flg_tec_DCChrMgmt_TxBRMSts_Flg: accessed-variable=RTE_R_DCChrMgmt_TxSts_Flg.tec_DCChrMgmt_TxBRMSts_Flg
            REC_RTE_R_DCChrMgmt_TxSts_Flg_tec_DCChrMgmt_TxBROSts_Flg: accessed-variable=RTE_R_DCChrMgmt_TxSts_Flg.tec_DCChrMgmt_TxBROSts_Flg
            REC_RTE_R_DCChrMgmt_TxSts_Flg_tec_DCChrMgmt_TxBSDSts_Flg: accessed-variable=RTE_R_DCChrMgmt_TxSts_Flg.tec_DCChrMgmt_TxBSDSts_Flg
            REC_RTE_R_DCChrMgmt_TxSts_Flg_tec_DCChrMgmt_TxBSMSts_Flg: accessed-variable=RTE_R_DCChrMgmt_TxSts_Flg.tec_DCChrMgmt_TxBSMSts_Flg
            REC_RTE_R_DCChrMgmt_TxSts_Flg_tec_DCChrMgmt_TxBSTSts_Flg: accessed-variable=RTE_R_DCChrMgmt_TxSts_Flg.tec_DCChrMgmt_TxBSTSts_Flg
            REC_CML_OutputCurrentMax_CML_OutputCurrentMax: accessed-variable=CML_OutputCurrentMax.CML_OutputCurrentMax
            REC_CCS_OutputCurrent_CCS_OutputCurrent: accessed-variable=CCS_OutputCurrent.CCS_OutputCurrent
            REC_SG_BMS_BatInfor_01_SigGroup_SG_BMS_BatInfor_01_SigGroup: accessed-variable=SG_BMS_BatInfor_01_SigGroup.SG_BMS_BatInfor_01_SigGroup
            REC_SG_BMS_BatInfor_02_SigGroup_SG_BMS_BatInfor_02_SigGroup: accessed-variable=SG_BMS_BatInfor_02_SigGroup.SG_BMS_BatInfor_02_SigGroup
            REC_SG_BMS_Charge_01_SigGroup_SG_BMS_Charge_01_SigGroup: accessed-variable=SG_BMS_Charge_01_SigGroup.SG_BMS_Charge_01_SigGroup
            REC_SG_BMS_Charge_03_SigGroup_SG_BMS_Charge_03_SigGroup: accessed-variable=SG_BMS_Charge_03_SigGroup.SG_BMS_Charge_03_SigGroup
            REC_SG_BMS_PRO_SigGroup_SG_BMS_PRO_SigGroup: accessed-variable=SG_BMS_PRO_SigGroup.SG_BMS_PRO_SigGroup
            REC_SG_BMS_TCU_SigGroup_SG_BMS_TCU_SigGroup: accessed-variable=SG_BMS_TCU_SigGroup.SG_BMS_TCU_SigGroup
            REC_SG_BMS_VersionInfor_SigGroup_SG_BMS_VersionInfor_SigGroup: accessed-variable=SG_BMS_VersionInfor_SigGroup.SG_BMS_VersionInfor_SigGroup
            REC_SG_BMS_status_03_SigGroup_SG_BMS_status_03_SigGroup: accessed-variable=SG_BMS_status_03_SigGroup.SG_BMS_status_03_SigGroup
            REC_SG_POD_Status_01_SigGroup_SG_POD_Status_01_SigGroup: accessed-variable=SG_POD_Status_01_SigGroup.SG_POD_Status_01_SigGroup
            REC_SG_BMS_CellTemp_SigGroup_SG_BMS_CellTemp_SigGroup: accessed-variable=SG_BMS_CellTemp_SigGroup.SG_BMS_CellTemp_SigGroup
            REC_SG_BMS_CellVoltage_SigGroup_SG_BMS_CellVoltage_SigGroup: accessed-variable=SG_BMS_CellVoltage_SigGroup.SG_BMS_CellVoltage_SigGroup
        data-send-points:
          87 x access:
            SEND_BCL_CurrentRequire_BCL_CurrentRequire: accessed-variable=BCL_CurrentRequire.BCL_CurrentRequire
            SEND_BCL_VolltageRequire_BCL_VolltageRequire: accessed-variable=BCL_VolltageRequire.BCL_VolltageRequire
            SEND_BEM_ChargeAbortTimeout_BEM_ChargeAbortTimeout: accessed-variable=BEM_ChargeAbortTimeout.BEM_ChargeAbortTimeout
            SEND_BEM_ChargeFinishTimeout_BEM_ChargeFinishTimeout: accessed-variable=BEM_ChargeFinishTimeout.BEM_ChargeFinishTimeout
            SEND_BEM_ChargeStateTimeout_BEM_ChargeStateTimeout: accessed-variable=BEM_ChargeStateTimeout.BEM_ChargeStateTimeout
            SEND_BEM_ChargeStatisticsTimeout_BEM_ChargeStatisticsTimeout: accessed-variable=BEM_ChargeStatisticsTimeout.BEM_ChargeStatisticsTimeout
            SEND_BEM_ChargerIdTimeout0_BEM_ChargerIdTimeout0: accessed-variable=BEM_ChargerIdTimeout0.BEM_ChargerIdTimeout0
            SEND_BEM_ChargerIdTimeout1_BEM_ChargerIdTimeout1: accessed-variable=BEM_ChargerIdTimeout1.BEM_ChargerIdTimeout1
            SEND_BEM_TimesyncOrPowerTimeout_BEM_TimesyncOrPowerTimeout: accessed-variable=BEM_TimesyncOrPowerTimeout.BEM_TimesyncOrPowerTimeout
            SEND_BHM_AllowChargeVoltageMax_BHM_AllowChargeVoltageMax: accessed-variable=BHM_AllowChargeVoltageMax.BHM_AllowChargeVoltageMax
            SEND_BRO_BMSChargeReady_BRO_BMSChargeReady: accessed-variable=BRO_BMSChargeReady.BRO_BMSChargeReady
            SEND_BSD_AbortSOC_BSD_AbortSOC: accessed-variable=BSD_AbortSOC.BSD_AbortSOC
            SEND_BSD_BatteryTempMax_BSD_BatteryTempMax: accessed-variable=BSD_BatteryTempMax.BSD_BatteryTempMax
            SEND_BSD_BatteryTempMin_BSD_BatteryTempMin: accessed-variable=BSD_BatteryTempMin.BSD_BatteryTempMin
            SEND_BSD_BatteryVoltageMax_BSD_BatteryVoltageMax: accessed-variable=BSD_BatteryVoltageMax.BSD_BatteryVoltageMax
            SEND_BSD_BatteryVoltageMin_BSD_BatteryVoltageMin: accessed-variable=BSD_BatteryVoltageMin.BSD_BatteryVoltageMin
            SEND_BSM_BatteryCurrentState_BSM_BatteryCurrentState: accessed-variable=BSM_BatteryCurrentState.BSM_BatteryCurrentState
            SEND_BSM_BatteryOutpuConnectorState_BSM_BatteryOutpuConnectorState: accessed-variable=BSM_BatteryOutpuConnectorState.BSM_BatteryOutpuConnectorState
            SEND_BSM_BatteryTempMax_BSM_BatteryTempMax: accessed-variable=BSM_BatteryTempMax.BSM_BatteryTempMax
            SEND_BSM_BatteryTempMaxNo_BSM_BatteryTempMaxNo: accessed-variable=BSM_BatteryTempMaxNo.BSM_BatteryTempMaxNo
            SEND_BSM_BatteryTempMin_BSM_BatteryTempMin: accessed-variable=BSM_BatteryTempMin.BSM_BatteryTempMin
            SEND_BSM_BatteryTempMinNo_BSM_BatteryTempMinNo: accessed-variable=BSM_BatteryTempMinNo.BSM_BatteryTempMinNo
            SEND_BSM_BatteryTempState_BSM_BatteryTempState: accessed-variable=BSM_BatteryTempState.BSM_BatteryTempState
            SEND_BSM_BatteryVoltageMaxNo_BSM_BatteryVoltageMaxNo: accessed-variable=BSM_BatteryVoltageMaxNo.BSM_BatteryVoltageMaxNo
            SEND_BSM_BatteryVoltageState_BSM_BatteryVoltageState: accessed-variable=BSM_BatteryVoltageState.BSM_BatteryVoltageState
            SEND_BSM_ChargeEnable_BSM_ChargeEnable: accessed-variable=BSM_ChargeEnable.BSM_ChargeEnable
            SEND_BSM_InsulationState_BSM_InsulationState: accessed-variable=BSM_InsulationState.BSM_InsulationState
            SEND_BSM_SOC_BSM_SOC: accessed-variable=BSM_SOC.BSM_SOC
            SEND_BST_AbortAchiveSOC_BST_AbortAchiveSOC: accessed-variable=BST_AbortAchiveSOC.BST_AbortAchiveSOC
            SEND_BST_AbortAchiveSingleVolt_BST_AbortAchiveSingleVolt: accessed-variable=BST_AbortAchiveSingleVolt.BST_AbortAchiveSingleVolt
            SEND_BST_AbortAchiveTotalVolt_BST_AbortAchiveTotalVolt: accessed-variable=BST_AbortAchiveTotalVolt.BST_AbortAchiveTotalVolt
            SEND_BST_AbortErrorCurrent_BST_AbortErrorCurrent: accessed-variable=BST_AbortErrorCurrent.BST_AbortErrorCurrent
            SEND_BST_AbortErrorVoltage_BST_AbortErrorVoltage: accessed-variable=BST_AbortErrorVoltage.BST_AbortErrorVoltage
            SEND_BST_AbortFaultBMSTemp_BST_AbortFaultBMSTemp: accessed-variable=BST_AbortFaultBMSTemp.BST_AbortFaultBMSTemp
            SEND_BST_AbortFaultBatteryTemp_BST_AbortFaultBatteryTemp: accessed-variable=BST_AbortFaultBatteryTemp.BST_AbortFaultBatteryTemp
            SEND_BST_AbortFaultConnector_BST_AbortFaultConnector: accessed-variable=BST_AbortFaultConnector.BST_AbortFaultConnector
            SEND_BST_AbortFaultConnectorTemp_BST_AbortFaultConnectorTemp: accessed-variable=BST_AbortFaultConnectorTemp.BST_AbortFaultConnectorTemp
            SEND_BST_AbortFaultInsulation_BST_AbortFaultInsulation: accessed-variable=BST_AbortFaultInsulation.BST_AbortFaultInsulation
            SEND_BST_AbortFaultOther_BST_AbortFaultOther: accessed-variable=BST_AbortFaultOther.BST_AbortFaultOther
            SEND_BST_AbortHVrelayfault_BST_AbortHVrelayfault: accessed-variable=BST_AbortHVrelayfault.BST_AbortHVrelayfault
            SEND_BST_Abortdet2Voltexception_BST_Abortdet2Voltexception: accessed-variable=BST_Abortdet2Voltexception.BST_Abortdet2Voltexception
            SEND_BST_Abortmanoperate_BST_Abortmanoperate: accessed-variable=BST_Abortmanoperate.BST_Abortmanoperate
            SEND_RTE_P_ComM_CMLMaxOutpIDc_A_tec_ComM_CMLMaxOutpIDc_A: accessed-variable=RTE_P_ComM_CMLMaxOutpIDc_A.tec_ComM_CMLMaxOutpIDc_A
            SEND_RTE_P_ComM_CMLMaxOutpUDc_V_tec_ComM_CMLMaxOutpUDc_V: accessed-variable=RTE_P_ComM_CMLMaxOutpUDc_V.tec_ComM_CMLMaxOutpUDc_V
            SEND_RTE_P_ComM_CMLMinOutpIDc_A_tec_ComM_CMLMinOutpIDc_A: accessed-variable=RTE_P_ComM_CMLMinOutpIDc_A.tec_ComM_CMLMinOutpIDc_A
            SEND_RTE_P_ComM_CMLMinOutpUDc_V_tec_ComM_CMLMinOutpUDc_V: accessed-variable=RTE_P_ComM_CMLMinOutpUDc_V.tec_ComM_CMLMinOutpUDc_V
            SEND_RTE_P_ComM_CRMRecgRes_Enum_tec_ComM_CRMRecgRes_Enum: accessed-variable=RTE_P_ComM_CRMRecgRes_Enum.tec_ComM_CRMRecgRes_Enum
            SEND_RTE_P_ComM_CROPrepRdy_Enum_tec_ComM_CROPrepRdy_Enum: accessed-variable=RTE_P_ComM_CROPrepRdy_Enum.tec_ComM_CROPrepRdy_Enum
            SEND_RTE_P_ComM_RxSts_Flg_tec_ComM_RxCCSSts_Flg: accessed-variable=RTE_P_ComM_RxSts_Flg.tec_ComM_RxCCSSts_Flg
            SEND_RTE_P_ComM_RxSts_Flg_tec_ComM_RxCEMSts_Flg: accessed-variable=RTE_P_ComM_RxSts_Flg.tec_ComM_RxCEMSts_Flg
            SEND_RTE_P_ComM_RxSts_Flg_tec_ComM_RxCHMSts_Flg: accessed-variable=RTE_P_ComM_RxSts_Flg.tec_ComM_RxCHMSts_Flg
            SEND_RTE_P_ComM_RxSts_Flg_tec_ComM_RxCMLSts_Flg: accessed-variable=RTE_P_ComM_RxSts_Flg.tec_ComM_RxCMLSts_Flg
            SEND_RTE_P_ComM_RxSts_Flg_tec_ComM_RxCRMSts_Flg: accessed-variable=RTE_P_ComM_RxSts_Flg.tec_ComM_RxCRMSts_Flg
            SEND_RTE_P_ComM_RxSts_Flg_tec_ComM_RxCROSts_Flg: accessed-variable=RTE_P_ComM_RxSts_Flg.tec_ComM_RxCROSts_Flg
            SEND_RTE_P_ComM_RxSts_Flg_tec_ComM_RxCSDSts_Flg: accessed-variable=RTE_P_ComM_RxSts_Flg.tec_ComM_RxCSDSts_Flg
            SEND_RTE_P_ComM_RxSts_Flg_tec_ComM_RxCSTSts_Flg: accessed-variable=RTE_P_ComM_RxSts_Flg.tec_ComM_RxCSTSts_Flg
            SEND_BCP_AllowChargeVoltageMax_BCP_AllowChargeVoltageMax: accessed-variable=BCP_AllowChargeVoltageMax.BCP_AllowChargeVoltageMax
            SEND_BCP_AllowTempMax_BCP_AllowTempMax: accessed-variable=BCP_AllowTempMax.BCP_AllowTempMax
            SEND_BCP_BatteryChargeVoltageMax_BCP_BatteryChargeVoltageMax: accessed-variable=BCP_BatteryChargeVoltageMax.BCP_BatteryChargeVoltageMax
            SEND_BCP_BatteryNominalEnergy_BCP_BatteryNominalEnergy: accessed-variable=BCP_BatteryNominalEnergy.BCP_BatteryNominalEnergy
            SEND_BCP_BatteryTotalVoltage_BCP_BatteryTotalVoltage: accessed-variable=BCP_BatteryTotalVoltage.BCP_BatteryTotalVoltage
            SEND_BCP_ChargeCurrentMax_BCP_ChargeCurrentMax: accessed-variable=BCP_ChargeCurrentMax.BCP_ChargeCurrentMax
            SEND_BCP_SOC_BCP_SOC: accessed-variable=BCP_SOC.BCP_SOC
            SEND_BCS_BatteryVoltMax_BCS_BatteryVoltMax: accessed-variable=BCS_BatteryVoltMax.BCS_BatteryVoltMax
            SEND_BCS_BatteryVoltMaxGroup_BCS_BatteryVoltMaxGroup: accessed-variable=BCS_BatteryVoltMaxGroup.BCS_BatteryVoltMaxGroup
            SEND_BCS_ChargeCurrentMeasure_BCS_ChargeCurrentMeasure: accessed-variable=BCS_ChargeCurrentMeasure.BCS_ChargeCurrentMeasure
            SEND_BCS_ChargeVoltageMeasure_BCS_ChargeVoltageMeasure: accessed-variable=BCS_ChargeVoltageMeasure.BCS_ChargeVoltageMeasure
            SEND_BCS_EstimatedTimeRemaining_BCS_EstimatedTimeRemaining: accessed-variable=BCS_EstimatedTimeRemaining.BCS_EstimatedTimeRemaining
            SEND_BCS_SOC_BCS_SOC: accessed-variable=BCS_SOC.BCS_SOC
            SEND_BRM_BatteryChargeTimes_BRM_BatteryChargeTimes: accessed-variable=BRM_BatteryChargeTimes.BRM_BatteryChargeTimes
            SEND_BRM_BatteryProductDay_BRM_BatteryProductDay: accessed-variable=BRM_BatteryProductDay.BRM_BatteryProductDay
            SEND_BRM_BatteryProductMonth_BRM_BatteryProductMonth: accessed-variable=BRM_BatteryProductMonth.BRM_BatteryProductMonth
            SEND_BRM_BatteryProductYear_BRM_BatteryProductYear: accessed-variable=BRM_BatteryProductYear.BRM_BatteryProductYear
            SEND_BRM_BatteryProperty_BRM_BatteryProperty: accessed-variable=BRM_BatteryProperty.BRM_BatteryProperty
            SEND_BRM_BatterySN_BRM_BatterySN: accessed-variable=BRM_BatterySN.BRM_BatterySN
            SEND_BRM_BatterySystemRatedCapacity_BRM_BatterySystemRatedCapacity: accessed-variable=BRM_BatterySystemRatedCapacity.BRM_BatterySystemRatedCapacity
            SEND_BRM_BatterySystemRatedVoltage_BRM_BatterySystemRatedVoltage: accessed-variable=BRM_BatterySystemRatedVoltage.BRM_BatterySystemRatedVoltage
            SEND_BRM_BatteryType_BRM_BatteryType: accessed-variable=BRM_BatteryType.BRM_BatteryType
            SEND_BRM_Manufacturer_BRM_Manufacturer: accessed-variable=BRM_Manufacturer.BRM_Manufacturer
            SEND_BRM_ProtocolVersion_BRM_ProtocolVersion: accessed-variable=BRM_ProtocolVersion.BRM_ProtocolVersion
            SEND_BRM_VehicleIdByte17_BRM_VehicleIdByte17: accessed-variable=BRM_VehicleIdByte17.BRM_VehicleIdByte17
            SEND_BRM_VehicleIdByte1_8_BRM_VehicleIdByte1_8: accessed-variable=BRM_VehicleIdByte1_8.BRM_VehicleIdByte1_8
            SEND_BRM_VehicleIdByte9_16_BRM_VehicleIdByte9_16: accessed-variable=BRM_VehicleIdByte9_16.BRM_VehicleIdByte9_16
            SEND_BCL_ChargeMode_BCL_ChargeMode: accessed-variable=BCL_ChargeMode.BCL_ChargeMode
            SEND_RTE_P_ComM_CCSOutpIDc_A_tec_ComM_CCSOutpIDc_A: accessed-variable=RTE_P_ComM_CCSOutpIDc_A.tec_ComM_CCSOutpIDc_A
            SEND_RTE_P_ComM_CCSOutpUDc_V_tec_ComM_CCSOutpUDc_V: accessed-variable=RTE_P_ComM_CCSOutpUDc_V.tec_ComM_CCSOutpUDc_V
            SEND_BST_AbortChargparameter_BST_AbortChargparameter: accessed-variable=BST_AbortChargparameter.BST_AbortChargparameter
      runnable R_DCComM_Init
  swc implementation CtAp_DCComM_Implementation: behavior=CtAp_DCComM_InternalBehavior
